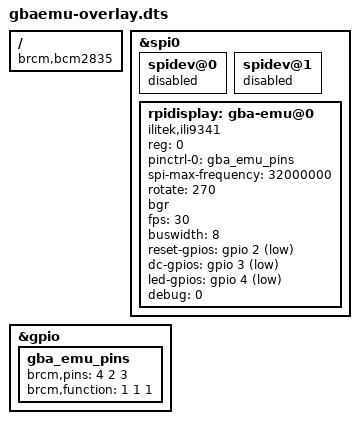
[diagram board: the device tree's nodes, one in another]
/*
 * Device Tree overlay for gba-emu by Ryzee119
 * See https://github.com/notro/fbtft/wiki/FBTFT-RPI-overlays for info on how to make your own
 */

/dts-v1/;
/plugin/;

/ {
	compatible = "brcm,bcm2835", "brcm,bcm2708", "brcm,bcm2709";

	fragment@0 {
		target = <&spi0>;
		__overlay__ {
			status = "okay";

			spidev@0{
				status = "disabled";
			};

			spidev@1{
				status = "disabled";
			};
		};
	};

	fragment@1 {
		target = <&gpio>;
		__overlay__ {
			gba_emu_pins: gba_emu_pins {
				brcm,pins = <4 2 3>;
				brcm,function = <1 1 1>; /* out out out*/
			};
		};
	};

	fragment@2 {
		target = <&spi0>;
		__overlay__ {
			/* needed to avoid dtc warning */
			#address-cells = <1>;
			#size-cells = <0>;

			rpidisplay: gba-emu@0{
				compatible = "ilitek,ili9341";
				reg = <0>;
				pinctrl-names = "default";
				pinctrl-0 = <&gba_emu_pins>;

				spi-max-frequency = <32000000>;
				rotate = <270>;
				bgr;
				fps = <30>;
				buswidth = <8>;
				reset-gpios = <&gpio 2 1>;
				dc-gpios = <&gpio 3 1>;
				led-gpios = <&gpio 4 1>;
				debug = <0>;
			};

		
		};
	};
	__overrides__ {
		speed =   <&rpidisplay>,"spi-max-frequency:0";
		rotate =  <&rpidisplay>,"rotate:0";
		fps =     <&rpidisplay>,"fps:0";
		debug =   <&rpidisplay>,"debug:0";
	};
};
